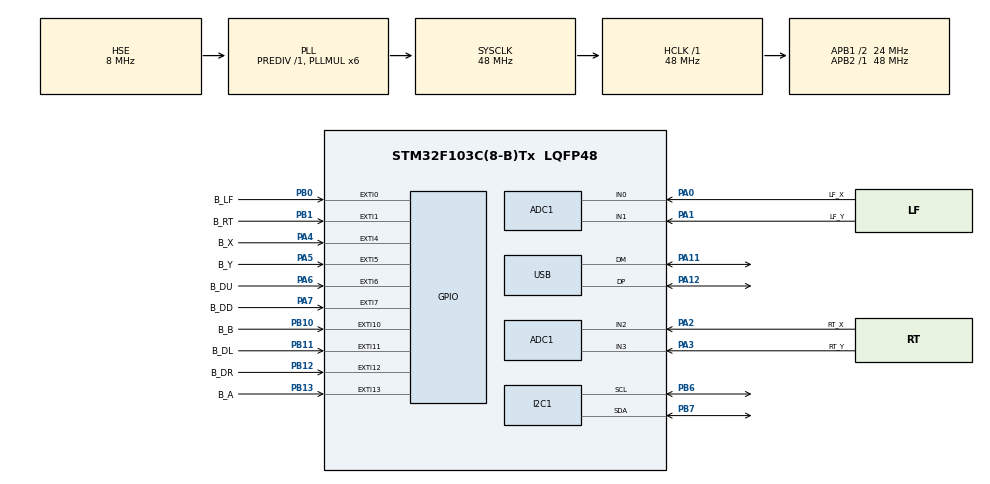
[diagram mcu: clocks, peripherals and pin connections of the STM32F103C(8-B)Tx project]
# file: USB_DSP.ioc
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ADC1.Channel-1\#ChannelRegularConversion=ADC_CHANNEL_0
ADC1.Channel-6\#ChannelRegularConversion=ADC_CHANNEL_1
ADC1.Channel-7\#ChannelRegularConversion=ADC_CHANNEL_2
ADC1.Channel-8\#ChannelRegularConversion=ADC_CHANNEL_3
ADC1.ContinuousConvMode=DISABLE
ADC1.EnableInjectedConversion=DISABLE
ADC1.EnableRegularConversion=ENABLE
ADC1.ExternalTrigConv=ADC_EXTERNALTRIGCONV_T3_TRGO
ADC1.InjNumberOfConversion=4
ADC1.NbrOfConversion=4
ADC1.NbrOfConversionFlag=1
ADC1.Rank-1\#ChannelRegularConversion=1
ADC1.Rank-6\#ChannelRegularConversion=2
ADC1.Rank-7\#ChannelRegularConversion=3
ADC1.Rank-8\#ChannelRegularConversion=4
ADC1.SamplingTime-1\#ChannelRegularConversion=ADC_SAMPLETIME_239CYCLES_5
ADC1.SamplingTime-6\#ChannelRegularConversion=ADC_SAMPLETIME_239CYCLES_5
ADC1.SamplingTime-7\#ChannelRegularConversion=ADC_SAMPLETIME_239CYCLES_5
ADC1.SamplingTime-8\#ChannelRegularConversion=ADC_SAMPLETIME_239CYCLES_5
ADC1.master=1
Dma.ADC1.0.Direction=DMA_PERIPH_TO_MEMORY
Dma.ADC1.0.Instance=DMA1_Channel1
Dma.ADC1.0.MemDataAlignment=DMA_MDATAALIGN_HALFWORD
Dma.ADC1.0.MemInc=DMA_MINC_ENABLE
Dma.ADC1.0.Mode=DMA_CIRCULAR
Dma.ADC1.0.PeriphDataAlignment=DMA_PDATAALIGN_HALFWORD
Dma.ADC1.0.PeriphInc=DMA_PINC_DISABLE
Dma.ADC1.0.Priority=DMA_PRIORITY_HIGH
Dma.Request0=ADC1
Mcu.Family=STM32F1
Mcu.Name=STM32F103C(8-B)Tx
Mcu.Package=LQFP48
NVIC.DMA1_Channel1_IRQn=true\:0\:0\:false\:false\:true\:false\:true\:true
NVIC.EXTI0_IRQn=true\:0\:0\:false\:false\:true\:true\:true\:true
NVIC.EXTI15_10_IRQn=true\:0\:0\:false\:false\:true\:true\:true\:true
NVIC.EXTI1_IRQn=true\:0\:0\:false\:false\:true\:true\:true\:true
NVIC.EXTI4_IRQn=true\:0\:0\:false\:false\:true\:true\:true\:true
NVIC.EXTI9_5_IRQn=true\:0\:0\:false\:false\:true\:true\:true\:true
NVIC.PriorityGroup=NVIC_PRIORITYGROUP_4
NVIC.TIM3_IRQn=true\:0\:0\:false\:false\:true\:true\:true\:true
NVIC.USB_HP_CAN1_TX_IRQn=true\:0\:0\:false\:false\:true\:true\:true\:true
NVIC.USB_LP_CAN1_RX0_IRQn=true\:0\:0\:false\:false\:true\:false\:true\:true
PA0-WKUP.GPIO_Label=LF_X
PA0-WKUP.Signal=ADCx_IN0
PA1.GPIO_Label=LF_Y
PA1.Signal=ADCx_IN1
PA11.Mode=Device
PA11.Signal=USB_DM
PA12.Mode=Device
PA12.Signal=USB_DP
PA13.Mode=Trace_Asynchronous_SW
PA13.Signal=SYS_JTMS-SWDIO
PA14.Mode=Trace_Asynchronous_SW
PA14.Signal=SYS_JTCK-SWCLK
PA2.GPIO_Label=RT_X
PA2.Signal=ADCx_IN2
PA3.GPIO_Label=RT_Y
PA3.Signal=ADCx_IN3
PA4.GPIO_Label=B_X
PA4.Signal=GPXTI4
PA5.GPIO_Label=B_Y
PA5.Signal=GPXTI5
PA6.GPIO_Label=B_DU
PA6.Signal=GPXTI6
PA7.GPIO_Label=B_DD
PA7.Signal=GPXTI7
PB0.GPIO_Label=B_LF
PB0.Signal=GPXTI0
PB1.GPIO_Label=B_RT
PB1.Signal=GPXTI1
PB10.GPIO_Label=B_B
PB10.Signal=GPXTI10
PB11.GPIO_Label=B_DL
PB11.Signal=GPXTI11
PB12.GPIO_Label=B_DR
PB12.Signal=GPXTI12
PB13.GPIO_Label=B_A
PB13.Signal=GPXTI13
PB3.Mode=Trace_Asynchronous_SW
PB3.Signal=SYS_JTDO-TRACESWO
PB6.Mode=I2C
PB6.Signal=I2C1_SCL
PB7.Mode=I2C
PB7.Signal=I2C1_SDA
PD0-OSC_IN.Mode=HSE-External-Oscillator
PD0-OSC_IN.Signal=RCC_OSC_IN
PD1-OSC_OUT.Mode=HSE-External-Oscillator
PD1-OSC_OUT.Signal=RCC_OSC_OUT
ProjectManager.HeapSize=0x200
ProjectManager.StackSize=0x400
ProjectManager.TargetToolchain=MDK-ARM V5.32
RCC.ADCPresc=RCC_ADCPCLK2_DIV4
RCC.AHBFreq_Value=48000000
RCC.APB1CLKDivider=RCC_HCLK_DIV2
RCC.APB1Freq_Value=24000000
RCC.APB1TimFreq_Value=48000000
RCC.APB2Freq_Value=48000000
RCC.APB2TimFreq_Value=48000000
RCC.HCLKFreq_Value=48000000
RCC.PLLMUL=RCC_PLL_MUL6
RCC.PLLSourceVirtual=RCC_PLLSOURCE_HSE
RCC.SYSCLKFreq_VALUE=48000000
RCC.SYSCLKSource=RCC_SYSCLKSOURCE_PLLCLK
RCC.USBFreq_Value=48000000
SH.ADCx_IN0.0=ADC1_IN0,IN0
SH.ADCx_IN1.0=ADC1_IN1,IN1
SH.ADCx_IN2.0=ADC1_IN2,IN2
SH.ADCx_IN3.0=ADC1_IN3,IN3
TIM3.Period=1000-1
TIM3.Prescaler=48-1
TIM3.TIM_MasterOutputTrigger=TIM_TRGO_UPDATE
TIM3.TIM_MasterSlaveMode=TIM_MASTERSLAVEMODE_ENABLE
USB_DEVICE.CLASS_NAME_FS=CUSTOM_HID
USB_DEVICE.USBD_CUSTOM_HID_REPORT_DESC_SIZE=66
USB_DEVICE.VirtualMode=CustomHid
USB_DEVICE.VirtualModeFS=Custom_Hid_FS
VP_TIM3_VS_ClockSourceINT.Mode=Internal
VP_USB_DEVICE_VS_USB_DEVICE_CUSTOM_HID_FS.Mode=CUSTOM_HID_FS
board=custom

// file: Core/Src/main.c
/* USER CODE BEGIN Header */
/**
  ******************************************************************************
  * @file           : main.c
  * @brief          : Main program body
  ******************************************************************************
  * @attention
  *
  * Copyright (c) 2026 STMicroelectronics.
  * All rights reserved.
  *
  * This software is licensed under terms that can be found in the LICENSE file
  * in the root directory of this software component.
  * If no LICENSE file comes with this software, it is provided AS-IS.
  *
  ******************************************************************************
  */
/* USER CODE END Header */
#include "main.h"
#include "adc.h"
#include "dma.h"
#include "i2c.h"
#include "tim.h"
#include "usb_device.h"
#include "gpio.h"

/* USER CODE BEGIN Includes */
#include "joystick.h"
#include "usbd_customhid.h"
/* USER CODE END Includes */

/* USER CODE BEGIN PD */
#define JOYSTICK_ADC_CHANNELS  4
/* USER CODE END PD */

/* USER CODE BEGIN PV */
uint16_t adc_buf[JOYSTICK_ADC_CHANNELS];  // DMA 循环写入的摇杆原始值

// 摇杆中心校准值
uint16_t adc_center[JOYSTICK_ADC_CHANNELS];
/* USER CODE END PV */

void SystemClock_Config(void);

/* USER CODE BEGIN 0 */
extern USBD_HandleTypeDef hUsbDeviceFS;
/* USER CODE END 0 */

int main(void)
{

  /* MCU Configuration--------------------------------------------------------*/

  /* Reset of all peripherals, Initializes the Flash interface and the Systick. */
  HAL_Init();

  /* Configure the system clock */
  SystemClock_Config();

  /* Initialize all configured peripherals */
  MX_GPIO_Init();
  MX_DMA_Init();
  MX_ADC1_Init();
  MX_I2C1_Init();
  MX_USB_DEVICE_Init();
  MX_TIM3_Init();
  /* USER CODE BEGIN 2 */
	Joystick_Init();
	    // ---- HID 报告缓冲区 ----
  uint8_t hid_report[7]; // [btn0][btn1][LX][LY][RX][RY]
  /* USER CODE END 2 */

  /* Infinite loop */
  /* USER CODE BEGIN WHILE */
  while (1)
  {
        // 1. 更新摇杆滤波 + 按键扫描（1ms 节奏）
        Joystick_Update();

        // 2. 填充 6 字节 HID 报告
        Joystick_FillHIDReport(hid_report);

        // 3. 通过 USB Custom HID 发送
        USBD_CUSTOM_HID_SendReport(&hUsbDeviceFS, hid_report, 7);

        // 4. 1ms 延时，和 TIM3 触发频率、ADC 采样率同步
        HAL_Delay(1);
    /* USER CODE END WHILE */

  }
}

void SystemClock_Config(void)
{
  RCC_OscInitTypeDef RCC_OscInitStruct = {0};
  RCC_ClkInitTypeDef RCC_ClkInitStruct = {0};
  RCC_PeriphCLKInitTypeDef PeriphClkInit = {0};

  /** Initializes the RCC Oscillators according to the specified parameters
  * in the RCC_OscInitTypeDef structure.
  */
  RCC_OscInitStruct.OscillatorType = RCC_OSCILLATORTYPE_HSE;
  RCC_OscInitStruct.HSEState = RCC_HSE_ON;
  RCC_OscInitStruct.HSEPredivValue = RCC_HSE_PREDIV_DIV1;
  RCC_OscInitStruct.HSIState = RCC_HSI_ON;
  RCC_OscInitStruct.PLL.PLLState = RCC_PLL_ON;
  RCC_OscInitStruct.PLL.PLLSource = RCC_PLLSOURCE_HSE;
  RCC_OscInitStruct.PLL.PLLMUL = RCC_PLL_MUL6;
  if (HAL_RCC_OscConfig(&RCC_OscInitStruct) != HAL_OK)
  {
    Error_Handler();
  }

  /** Initializes the CPU, AHB and APB buses clocks
  */
  RCC_ClkInitStruct.ClockType = RCC_CLOCKTYPE_HCLK|RCC_CLOCKTYPE_SYSCLK
                              |RCC_CLOCKTYPE_PCLK1|RCC_CLOCKTYPE_PCLK2;
  RCC_ClkInitStruct.SYSCLKSource = RCC_SYSCLKSOURCE_PLLCLK;
  RCC_ClkInitStruct.AHBCLKDivider = RCC_SYSCLK_DIV1;
  RCC_ClkInitStruct.APB1CLKDivider = RCC_HCLK_DIV2;
  RCC_ClkInitStruct.APB2CLKDivider = RCC_HCLK_DIV1;

  if (HAL_RCC_ClockConfig(&RCC_ClkInitStruct, FLASH_LATENCY_1) != HAL_OK)
  {
    Error_Handler();
  }
  PeriphClkInit.PeriphClockSelection = RCC_PERIPHCLK_ADC|RCC_PERIPHCLK_USB;
  PeriphClkInit.AdcClockSelection = RCC_ADCPCLK2_DIV4;
  PeriphClkInit.UsbClockSelection = RCC_USBCLKSOURCE_PLL;
  if (HAL_RCCEx_PeriphCLKConfig(&PeriphClkInit) != HAL_OK)
  {
    Error_Handler();
  }
}

void Error_Handler(void)
{
  __disable_irq();
  while (1)
  {
  }
}
